# PY32T020xx register map
Vendor: Puya; Series: PY32L0; File version: 1.0.0
CPU: CM0+ r0p1, little endian, no MPU, no FPU, 4 interrupt priority bits
Registers are 32-bit, read-write, reset 0x0 unless marked. A register's access mark holds for its fields unless they carry their own. Offsets are from the block's base; [hi:lo] are bit positions.

## TK — Touch key
Base 0x40003800
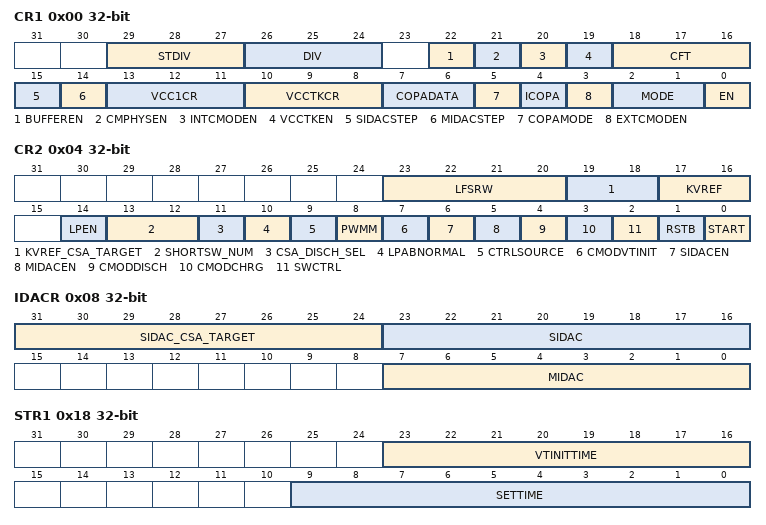
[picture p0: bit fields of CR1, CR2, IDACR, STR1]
0x00 CR1 — Control register 1
  [29:27] STDIV — PCLK division(ST_CLK)
  [26:24] DIV — PCLK division(TK_CLK)
  [22] BUFFEREN — Discharge buffer enable
  [21] CMPHYSEN — CMP hysteresis enable
  [20] INTCMODEN — Internal CMOD enable
  [19] VCCTKEN — VCCTK voltage enable
  [18:16] CFT — CMP OUT filter select
  [15] SIDACSTEP — SIDAC step select
  [14] MIDACSTEP — MIDAC step select
  [13:11] VCC1CR — VCC1 voltage select
  [10:8] VCCTKCR — VCCTK voltage select
  [7:6] COPADATA — unsensed key output control
  [5] COPAMODE — Key compensation enable
  [4] ICOPA — SIDAC source current or sink current select
  [3] EXTCMODEN — External CMOD enable
  [2:1] MODE — TK mode select
  [0] EN — TK enable
0x04 CR2 — Control register 2
  [23:20] LFSRW — LFSR valid bit
  [19:18] KVREF_CSA_TARGET — Vref charging target value in CSA mode
  [17:16] KVREF — Reference voltage select
  [14] LPEN — Lowpower wake up enable
  [13:12] SHORTSW_NUM — Short switch times of hardware mode in CSD mode
  [11] CSA_DISCH_SEL — CMOD discharge select in CSA mode
  [10] LPABNORMAL — Lowpower wake up control
  [9] CTRLSOURCE — Software or hardware select
  [8] PWMM — PWM mode select
  [7] CMODVTINIT — The voltage of CMOD initialization
  [6] SIDACEN — Slave IDAC enable
  [5] MIDACEN — Main IDAC enable
  [4] CMODDISCH — CMOD discharge enable
  [3] CMODCHRG — CMOD charge enable
  [2] SWCTRL — TK_SW control
  [1] RSTB — Counter reset
  [0] START — Sense start
0x08 IDACR — IDAC Control register
  [31:24] SIDAC_CSA_TARGET — SIDAC target value in CSA mode
  [23:16] SIDAC — Slave IDAC configuration
  [7:0] MIDAC — Main IDAC configuration
0x0C KR — Key enable register
  [25:0] KEN — Sense function enable
0x10 CSR — Channel Select register
  [25:0] CHS — Sense key select
0x14 UCR — Unsel Control register
  [25:0] COPAMODEIO — IO compensation enable
0x18 STR1 — Stable Time register 1
  [23:16] VTINITTIME — CMOD dischsrge time in CSA mode
  [9:0] SETTIME — Voltage building time in CSA mode or short switch time in CSD mode or discharge time in PCI mode
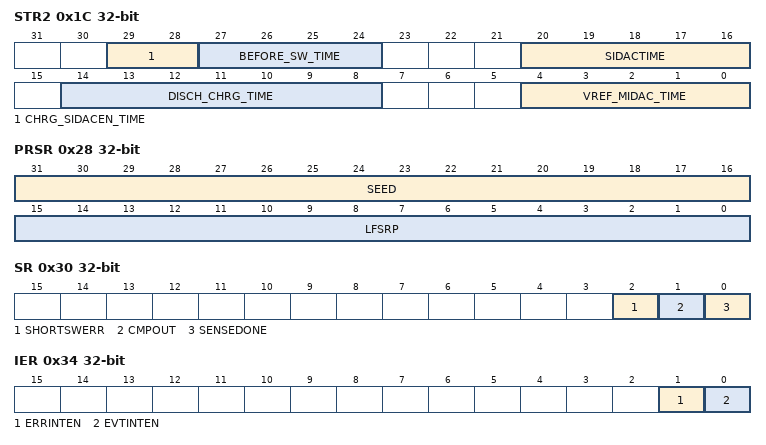
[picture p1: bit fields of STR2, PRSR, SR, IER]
0x1C STR2 — Stable Time register 2
  [29:28] CHRG_SIDACEN_TIME — From clearing CMODCHRG to setting SIDACEN time in CSA mode
  [27:24] BEFORE_SW_TIME — From setting SIDACEN to switching TK_SW time in CSA mode or from clearing CMODDISCH to switching TK_SW time in PCI mode
  [20:16] SIDACTIME — SIDAC stabilization time in CSA mode
  [14:8] DISCH_CHRG_TIME — CMOD discharging or charging time in CSA mode
  [4:0] VREF_MIDAC_TIME — VREF or MIDAC stabilization time in CSA mode
0x20 WR — Window register
  [15:0] WIN — Window time
0x24 SDR — Switch Divide register
  [8:0] SWDIV — TK_CLK division(TK_SW)
0x28 PRSR — Pseudo Random Sequence register
  [31:16] SEED — LFSR seed
  [15:0] LFSRP — LFSR polynomial
0x2C DR — Data register
  [15:0] DATA ro — Sense data
0x30 SR — Status register
  [2] SHORTSWERR ro — Short switch error of hardware in CSD mode
  [1] CMPOUT ro — CMP output
  [0] SENSEDONE ro — Sense finished
0x34 IER — Interrupt enable register
  [1] ERRINTEN — Error interrupt enable
  [0] EVTINTEN — Event interrupt enable
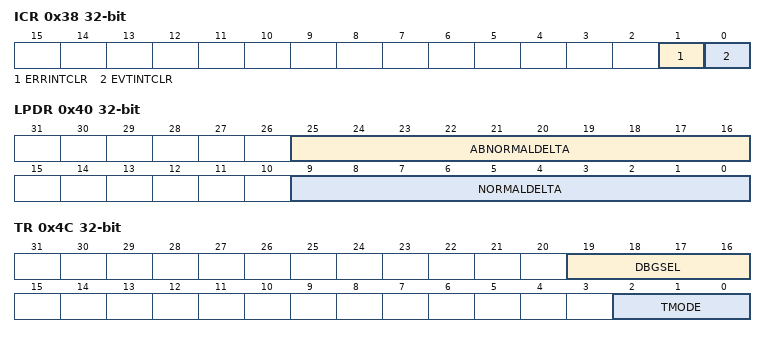
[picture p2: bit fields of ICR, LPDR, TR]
0x38 ICR — Interrupt clear register
  [1] ERRINTCLR — Error interrupt clear
  [0] EVTINTCLR — Event interrupt clear
0x3C CDR — Compare Data register
  [15:0] CDATA — Compare data in lowpower
0x40 LPDR — Lowpower Delta register
  [25:16] ABNORMALDELTA — Delta2
  [9:0] NORMALDELTA — Delta1
0x44 LPTR — Lowpower Time register
  [6:0] LPWAIT — Wait time in lowpower
0x48 OPR
  [5:0] OP — CMP control
0x4C TR
  [19:16] DBGSEL — Debug signal select
  [2:0] TMODE — Test mode select
0x50 DDR
  [9:0] SHORTSW_DATA ro — Short switch data in CSD mode
